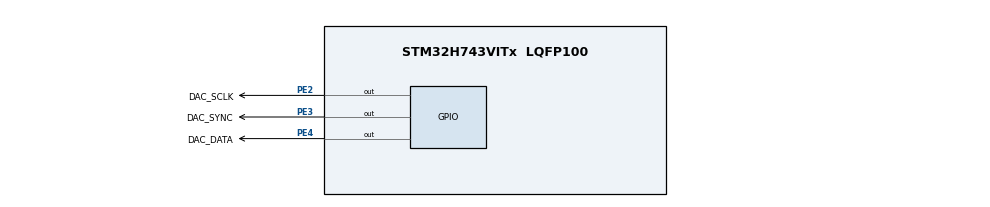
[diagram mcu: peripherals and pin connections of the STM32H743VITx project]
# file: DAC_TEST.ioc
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CORTEX_M7.default_mode_Activation=0
Mcu.Family=STM32H7
Mcu.Name=STM32H743VITx
Mcu.Package=LQFP100
NVIC.PriorityGroup=NVIC_PRIORITYGROUP_4
PA13\ (JTMS/SWDIO).Mode=Serial_Wire
PA13\ (JTMS/SWDIO).Signal=DEBUG_JTMS-SWDIO
PA14\ (JTCK/SWCLK).Mode=Serial_Wire
PA14\ (JTCK/SWCLK).Signal=DEBUG_JTCK-SWCLK
PE2.GPIO_Label=DAC_SCLK
PE2.GPIO_Speed=GPIO_SPEED_FREQ_VERY_HIGH
PE2.PinState=GPIO_PIN_SET
PE2.Signal=GPIO_Output
PE3.GPIO_Label=DAC_SYNC
PE3.GPIO_Speed=GPIO_SPEED_FREQ_VERY_HIGH
PE3.PinState=GPIO_PIN_SET
PE3.Signal=GPIO_Output
PE4.GPIO_Label=DAC_DATA
PE4.GPIO_Speed=GPIO_SPEED_FREQ_VERY_HIGH
PE4.Signal=GPIO_Output
PH0-OSC_IN\ (PH0).Mode=HSE-External-Oscillator
PH0-OSC_IN\ (PH0).Signal=RCC_OSC_IN
PH1-OSC_OUT\ (PH1).Mode=HSE-External-Oscillator
PH1-OSC_OUT\ (PH1).Signal=RCC_OSC_OUT
ProjectManager.HeapSize=0x200
ProjectManager.StackSize=0x400
ProjectManager.TargetToolchain=MDK-ARM V5.32
RCC.ADCFreq_Value=50390625
RCC.APB1Freq_Value=100000000
RCC.APB2Freq_Value=100000000
RCC.APB3Freq_Value=100000000
RCC.APB4Freq_Value=100000000
RCC.CortexFreq_Value=200000000
RCC.DIVM1=2
RCC.DIVN1=32
RCC.HCLKFreq_Value=100000000
RCC.HPRE=RCC_HCLK_DIV2
RCC.PLLFRACN=0
RCC.PLLSourceVirtual=RCC_PLLSOURCE_HSE
RCC.SYSCLKFreq_VALUE=200000000
RCC.SYSCLKSource=RCC_SYSCLKSOURCE_PLLCLK
RCC.USBFreq_Value=200000000
TIM7.Prescaler=50
VP_TIM7_VS_ClockSourceINT.Mode=Enable_Timer
board=custom

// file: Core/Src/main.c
/* USER CODE BEGIN Header */
/**
  ******************************************************************************
  * @file           : main.c
  * @brief          : Main program body
  ******************************************************************************
  * @attention
  *
  * Copyright (c) 2022 STMicroelectronics.
  * All rights reserved.
  *
  * This software is licensed under terms that can be found in the LICENSE file
  * in the root directory of this software component.
  * If no LICENSE file comes with this software, it is provided AS-IS.
  *
  ******************************************************************************
  */
/* USER CODE END Header */
#include "main.h"
#include "tim.h"
#include "gpio.h"

void SystemClock_Config(void);

int main(void)
{

  /* MCU Configuration--------------------------------------------------------*/

  /* Reset of all peripherals, Initializes the Flash interface and the Systick. */
  HAL_Init();

  /* USER CODE BEGIN Init */
	int32_t test = 0;
  /* USER CODE END Init */

  /* Configure the system clock */
  SystemClock_Config();

  /* Initialize all configured peripherals */
  MX_GPIO_Init();
  MX_TIM7_Init();

  /* Infinite loop */
  /* USER CODE BEGIN WHILE */

  while (1)
  {
		for(uint16_t i=0 ;i<200 ;i+=5)
		{
			//test = cal_dac(3000,i);
			voltage_output(sinbox[i]);

//			Delay_Us(50);
		}

    /* USER CODE END WHILE */

  }
}

void SystemClock_Config(void)
{
  RCC_OscInitTypeDef RCC_OscInitStruct = {0};
  RCC_ClkInitTypeDef RCC_ClkInitStruct = {0};

  /** Supply configuration update enable
  */
  HAL_PWREx_ConfigSupply(PWR_LDO_SUPPLY);

  /** Configure the main internal regulator output voltage
  */
  __HAL_PWR_VOLTAGESCALING_CONFIG(PWR_REGULATOR_VOLTAGE_SCALE3);

  while(!__HAL_PWR_GET_FLAG(PWR_FLAG_VOSRDY)) {}

  /** Initializes the RCC Oscillators according to the specified parameters
  * in the RCC_OscInitTypeDef structure.
  */
  RCC_OscInitStruct.OscillatorType = RCC_OSCILLATORTYPE_HSE;
  RCC_OscInitStruct.HSEState = RCC_HSE_ON;
  RCC_OscInitStruct.PLL.PLLState = RCC_PLL_ON;
  RCC_OscInitStruct.PLL.PLLSource = RCC_PLLSOURCE_HSE;
  RCC_OscInitStruct.PLL.PLLM = 2;
  RCC_OscInitStruct.PLL.PLLN = 32;
  RCC_OscInitStruct.PLL.PLLP = 2;
  RCC_OscInitStruct.PLL.PLLQ = 2;
  RCC_OscInitStruct.PLL.PLLR = 2;
  RCC_OscInitStruct.PLL.PLLRGE = RCC_PLL1VCIRANGE_3;
  RCC_OscInitStruct.PLL.PLLVCOSEL = RCC_PLL1VCOWIDE;
  RCC_OscInitStruct.PLL.PLLFRACN = 0;
  if (HAL_RCC_OscConfig(&RCC_OscInitStruct) != HAL_OK)
  {
    Error_Handler();
  }

  /** Initializes the CPU, AHB and APB buses clocks
  */
  RCC_ClkInitStruct.ClockType = RCC_CLOCKTYPE_HCLK|RCC_CLOCKTYPE_SYSCLK
                              |RCC_CLOCKTYPE_PCLK1|RCC_CLOCKTYPE_PCLK2
                              |RCC_CLOCKTYPE_D3PCLK1|RCC_CLOCKTYPE_D1PCLK1;
  RCC_ClkInitStruct.SYSCLKSource = RCC_SYSCLKSOURCE_PLLCLK;
  RCC_ClkInitStruct.SYSCLKDivider = RCC_SYSCLK_DIV1;
  RCC_ClkInitStruct.AHBCLKDivider = RCC_HCLK_DIV2;
  RCC_ClkInitStruct.APB3CLKDivider = RCC_APB3_DIV1;
  RCC_ClkInitStruct.APB1CLKDivider = RCC_APB1_DIV1;
  RCC_ClkInitStruct.APB2CLKDivider = RCC_APB2_DIV1;
  RCC_ClkInitStruct.APB4CLKDivider = RCC_APB4_DIV1;

  if (HAL_RCC_ClockConfig(&RCC_ClkInitStruct, FLASH_LATENCY_2) != HAL_OK)
  {
    Error_Handler();
  }
}

void Error_Handler(void)
{
  __disable_irq();
  while (1)
  {
  }
}
